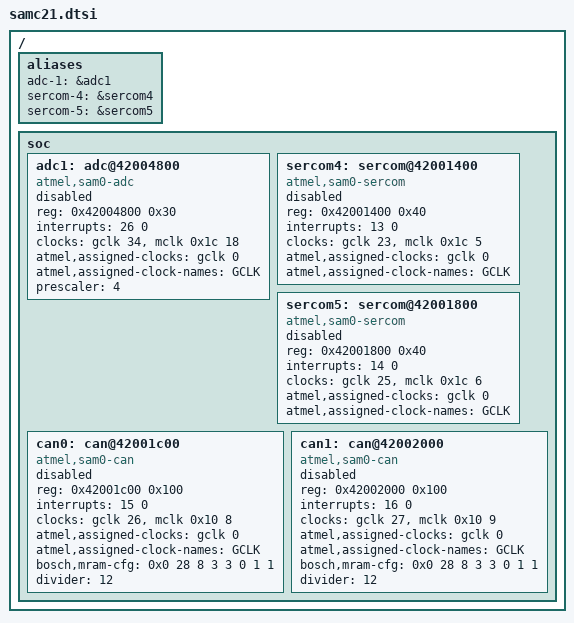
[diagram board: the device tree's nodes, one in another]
/*
 * Copyright (c) 2022 Kamil Serwus
 * Copyright (c) 2024 Gerson Fernando Budke <nandojve@gmail.com>
 *
 * SPDX-License-Identifier: Apache-2.0
 */

 #include <atmel/samc2x.dtsi>

/ {
	aliases {
		adc-1 = &adc1;

		sercom-4 = &sercom4;
		sercom-5 = &sercom5;
	};

	soc {
		adc1: adc@42004800 {
			compatible = "atmel,sam0-adc";
			reg = <0x42004800 0x30>;
			interrupts = <26 0>;
			interrupt-names = "resrdy";
			clocks = <&gclk 34>, <&mclk 0x1c 18>;
			clock-names = "GCLK", "MCLK";
			atmel,assigned-clocks = <&gclk 0>;
			atmel,assigned-clock-names = "GCLK";
			status = "disabled";

			#io-channel-cells = <1>;

			prescaler = <4>;
		};

		sercom4: sercom@42001400 {
			compatible = "atmel,sam0-sercom";
			reg = <0x42001400 0x40>;
			interrupts = <13 0>;
			clocks = <&gclk 23>, <&mclk 0x1c 5>;
			clock-names = "GCLK", "MCLK";
			atmel,assigned-clocks = <&gclk 0>;
			atmel,assigned-clock-names = "GCLK";
			status = "disabled";
		};

		sercom5: sercom@42001800 {
			compatible = "atmel,sam0-sercom";
			reg = <0x42001800 0x40>;
			interrupts = <14 0>;
			clocks = <&gclk 25>, <&mclk 0x1c 6>;
			clock-names = "GCLK", "MCLK";
			atmel,assigned-clocks = <&gclk 0>;
			atmel,assigned-clock-names = "GCLK";
			status = "disabled";
		};

		can0: can@42001c00 {
			compatible = "atmel,sam0-can";
			reg = <0x42001c00 0x100>;
			interrupts = <15 0>;
			interrupt-names = "int0";
			clocks = <&gclk 26>, <&mclk 0x10 8>;
			clock-names = "GCLK", "MCLK";
			atmel,assigned-clocks = <&gclk 0>;
			atmel,assigned-clock-names = "GCLK";
			status = "disabled";

			bosch,mram-cfg = <0x0 28 8 3 3 0 1 1>;
			divider = <12>;
		};

		can1: can@42002000 {
			compatible = "atmel,sam0-can";
			reg = <0x42002000 0x100>;
			interrupts = <16 0>;
			interrupt-names = "int0";
			clocks = <&gclk 27>, <&mclk 0x10 9>;
			clock-names = "GCLK", "MCLK";
			atmel,assigned-clocks = <&gclk 0>;
			atmel,assigned-clock-names = "GCLK";
			status = "disabled";

			bosch,mram-cfg = <0x0 28 8 3 3 0 1 1>;
			divider = <12>;
		};
	};
};
